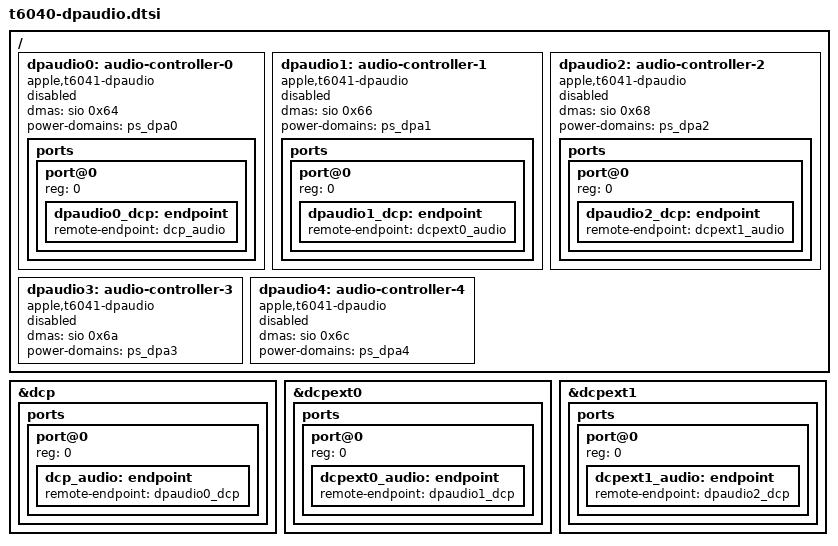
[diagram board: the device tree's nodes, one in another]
// SPDX-License-Identifier: GPL-2.0+ OR MIT
/*
 * DPA interfaces are fed by SIO and have no AP-side MMIO registers.
 * Keep them disabled until the T6041 SIO firmware and DCP audio services
 * are supported. DPA3/4 have no assigned DCP in this SoC's firmware tree.
 */

/ {
	dpaudio0: audio-controller-0 {
		compatible = "apple,t6041-dpaudio", "apple,dpaudio";
		dmas = <&sio 0x64>;
		dma-names = "tx";
		power-domains = <&ps_dpa0>;
		status = "disabled";

		ports {
			#address-cells = <1>;
			#size-cells = <0>;

			port@0 {
				reg = <0>;

				dpaudio0_dcp: endpoint {
					remote-endpoint = <&dcp_audio>;
				};
			};
		};
	};

	dpaudio1: audio-controller-1 {
		compatible = "apple,t6041-dpaudio", "apple,dpaudio";
		dmas = <&sio 0x66>;
		dma-names = "tx";
		power-domains = <&ps_dpa1>;
		status = "disabled";

		ports {
			#address-cells = <1>;
			#size-cells = <0>;

			port@0 {
				reg = <0>;

				dpaudio1_dcp: endpoint {
					remote-endpoint = <&dcpext0_audio>;
				};
			};
		};
	};

	dpaudio2: audio-controller-2 {
		compatible = "apple,t6041-dpaudio", "apple,dpaudio";
		dmas = <&sio 0x68>;
		dma-names = "tx";
		power-domains = <&ps_dpa2>;
		status = "disabled";

		ports {
			#address-cells = <1>;
			#size-cells = <0>;

			port@0 {
				reg = <0>;

				dpaudio2_dcp: endpoint {
					remote-endpoint = <&dcpext1_audio>;
				};
			};
		};
	};

	dpaudio3: audio-controller-3 {
		compatible = "apple,t6041-dpaudio", "apple,dpaudio";
		dmas = <&sio 0x6a>;
		dma-names = "tx";
		power-domains = <&ps_dpa3>;
		status = "disabled";
	};

	dpaudio4: audio-controller-4 {
		compatible = "apple,t6041-dpaudio", "apple,dpaudio";
		dmas = <&sio 0x6c>;
		dma-names = "tx";
		power-domains = <&ps_dpa4>;
		status = "disabled";
	};
};

&dcp {
	ports {
		#address-cells = <1>;
		#size-cells = <0>;

		port@0 {
			reg = <0>;

			dcp_audio: endpoint {
				remote-endpoint = <&dpaudio0_dcp>;
			};
		};
	};
};

&dcpext0 {
	ports {
		#address-cells = <1>;
		#size-cells = <0>;

		port@0 {
			reg = <0>;

			dcpext0_audio: endpoint {
				remote-endpoint = <&dpaudio1_dcp>;
			};
		};
	};
};

&dcpext1 {
	ports {
		#address-cells = <1>;
		#size-cells = <0>;

		port@0 {
			reg = <0>;

			dcpext1_audio: endpoint {
				remote-endpoint = <&dpaudio2_dcp>;
			};
		};
	};
};
